# YC3122 register map
Series: ARMCM0; File version: 1.0
CPU: CM0 r1p0, little endian, no MPU, no FPU, 8 interrupt priority bits
Registers are 32-bit, read-write, reset 0x0 unless marked. A register's access mark holds for its fields unless they carry their own. Offsets are from the block's base; [hi:lo] are bit positions.

## MRCC
Base 0x000F8400
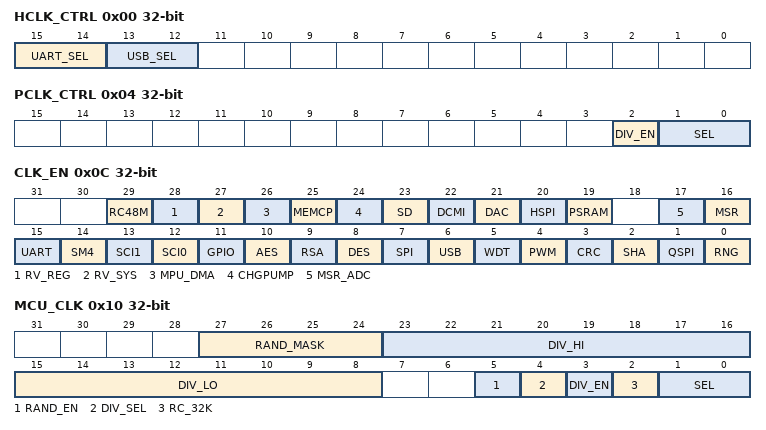
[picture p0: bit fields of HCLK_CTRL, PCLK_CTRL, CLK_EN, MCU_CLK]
0x00 HCLK_CTRL
  [15:14] UART_SEL — UART时钟clk_uart选择。 0: rc192m分频后生成的48M时钟 1: pll_hsi_48m,切换PLL频率会抖动 2: pll_hse_48m,切换PLL频率会抖动
  [13:12] USB_SEL — USB时钟clk_usb选择。 0: rc192m分频后生成的48M时钟 1: pll_hsi_48m,切换PLL频率会抖动 2: pll_hse_48m,切换PLL频率会抖动
0x04 PCLK_CTRL
  [2] DIV_EN — PCLK分频使能
  [1:0] SEL — PCLK使用的分频值选择 0: 1分频 1: 2分频 2: 4分频 3: 8分频
0x08 RSA_CLK
  [3:0] CLK_CFG — 每16个clk_rsa中,前n个可以强制为0,此 寄存器用于选择n值,从这里输出的时钟最终给到RSA模块1 : 每16个clk_rsa中,前3个周期强制为0. 2, 4, 5 :每16个clk_rsa中,前2个周期强 制为0. 3 : 每16个clk_rsa中,第一个强制为0. 6, 7 :clk_rsa输入等于输出 Others : 每16个clk_rsa中,前7个周期强 制为0
0x0C CLK_EN
  [29] RC48M — RC48M数字模块时钟开关
  [28] RV_REG — RV_REG数字模块时钟开关
  [27] RV_SYS — RV_SYS数字模块时钟开关
  [26] MPU_DMA — MPU_DMA数字模块时钟开关
  [25] MEMCP — MEMCP数字模块时钟开关
  [24] CHGPUMP — CHGPUMP数字模块时钟开关
  [23] SD — SD数字模块时钟开关
  [22] DCMI — DCMI数字模块时钟开关
  [21] DAC — DAC数字模块时钟开关
  [20] HSPI — HSPI数字模块时钟开关
  [19] PSRAM — PSRAM数字模块时钟开关
  [17] MSR_ADC — 7811_ADC数字模块时钟开关
  [16] MSR — 7811数字模块时钟开关
  [15] UART — UART数字模块时钟开关
  [14] SM4 — SM4数字模块时钟开关
  [13] SCI1 — SCI1数字模块时钟开关
  [12] SCI0 — SCI0数字模块时钟开关
  [11] GPIO — GPIO数字模块时钟开关
  [10] AES — AES数字模块时钟开关
  [9] RSA — RSA数字模块时钟开关
  [8] DES — DES数字模块时钟开关
  [7] SPI — SPI数字模块时钟开关
  [6] USB — USB数字模块时钟开关
  [5] WDT — WDT数字模块时钟开关
  [4] PWM — PWM数字模块时钟开关
  [3] CRC — CRC数字模块时钟开关
  [2] SHA — SHA数字模块时钟开关
  [1] QSPI — qspi数字模块时钟开关
  [0] RNG — rng数字模块时钟开关
0x10 MCU_CLK
  [27:24] RAND_MASK — DIV_HI和DIV_LO会加上(随机数& RA. ND_MASK)
  [23:16] DIV_HI — 输入给MCU的时钟的低电平持续时间 = (DIV _HI +1)个clk
  [15:8] DIV_LO — 输入给MCU的时钟的低电平持续时间 = (DIV _LO+1)个clk
  [5] RAND_EN — 为1则使能MCU时钟随机功能
  [4] DIV_SEL — MCU时钟分频选择 0：选择非分频时钟作为 clk_mcu. 1：选择分频时钟作为clk_mcu 注意：当从'1'变为'0'时,应先设置div_sel为' 0',延迟至少两个周期,然后清除div_en,不要同时清 除这两位。当从'0'变为'1'时,应先设置div_en为 '1',延迟至少两个周期,然后设置
  [3] DIV_EN — 为1则使能MCU时钟分频
  [2] RC_32K — 为1则使能内部RC32K（LSI）为系统时钟,同 时屏蔽其他所有的设置
  [1:0] SEL — MCU时钟来源选择 0: rc192m. 1: pll_192M. 2: pll_256M. 3: pll_48M,
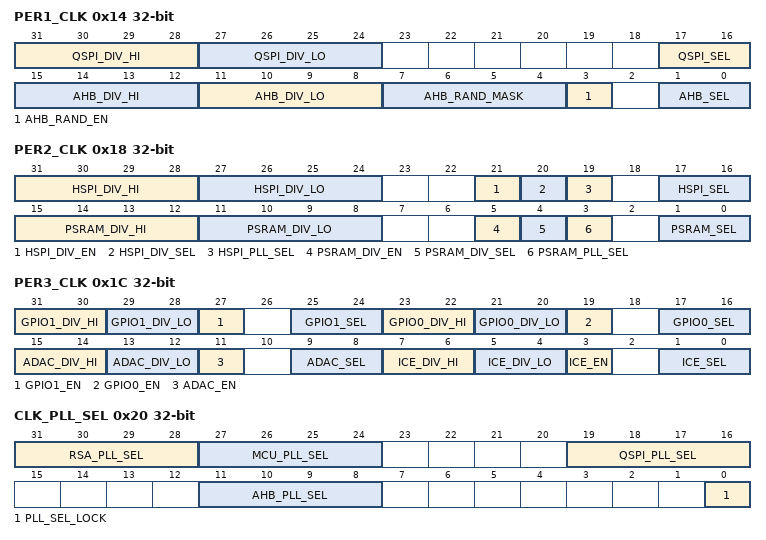
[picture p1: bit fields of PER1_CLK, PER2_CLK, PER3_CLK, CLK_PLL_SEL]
0x14 PER1_CLK
  [31:28] QSPI_DIV_HI — 输入给QSPI的时钟的低电平持续时间 = (QS. PI_DIV_HI+1)个clk
  [27:24] QSPI_DIV_LO — 输入给QSPI的时钟的低电平持续时间 = (QS. PI_DIV_LO+1)个clk
  [17:16] QSPI_SEL — QSPI总线时钟来源选择 0: CLK_MCU. 1: RC192M. 2: pll_192M. 3: pll_48M
  [15:12] AHB_DIV_HI — 输入给AHB的时钟的高电平持续时间 = (AHB _DIV_HI +1)个clk
  [11:8] AHB_DIV_LO — 输入给AHB的时钟的低电平持续时间 = (AHB _DIV_LO+1)个clk
  [7:4] AHB_RAND_MASK — AHB_DIV_HI和AHB_DIV_LO会加上 (随机数&AHB_RAND_MASK)
  [3] AHB_RAND_EN — 为1则使能AHB总线时钟随机功能
  [1:0] AHB_SEL — AHB总线时钟来源选择 0: CLK_MCU. 1: RC192M. 2: pll_192M. 3: pll_48M
0x18 PER2_CLK
  [31:28] HSPI_DIV_HI — 输入给HSPI的时钟的高电平持续时间 = (HS. PI_DIV_HI +1)个clk
  [27:24] HSPI_DIV_LO — 输入给HSPI的时钟的低电平持续时间 = (HS. PI_DIV_LO+1)个clk
  [21] HSPI_DIV_EN — 为1则使能HSPI时钟分频
  [20] HSPI_DIV_SEL — HSPI时钟分频选择 0：选择非分频时钟作为 clk_hspi. 1：选择分频时钟作为 clk_hspi
  [19] HSPI_PLL_SEL — HSPI时钟来源选择 0: pll_hsi. 1: pll_hse
  [17:16] HSPI_SEL — PSRAM总线时钟来源选择 0: CLK_MCU. 1: RC192M. 2: pll_192M. 3: pll_256M
  [15:12] PSRAM_DIV_HI — 输入给PSRAM的时钟的高电平持续时间 = (P. SRAM_DIV_HI +1)个clk
  [11:8] PSRAM_DIV_LO — 输入给PSRAM的时钟的低电平持续时间 = (P. SRAM_DIV_LO+1)个clk
  [5] PSRAM_DIV_EN — 为1则使能PSRAM时钟分频
  [4] PSRAM_DIV_SEL — PSRAM时钟分频选择 0：选择非分频时钟作为 clk_psram. 1：选择分频时钟作为clk_psram
  [3] PSRAM_PLL_SEL — PSRAM时钟来源选择 0: pll_hsi. 1: pll_hse
  [1:0] PSRAM_SEL — PSRAM总线时钟来源选择 0: CLK_MCU. 1: RC192M. 2: pll_192M. 3: pll_256M
0x1C PER3_CLK
  [31:30] GPIO1_DIV_HI — GPIO奇数脚输出的时钟的高电平持续时间 = ( GPIO1_DIV_HI+1)个clk
  [29:28] GPIO1_DIV_LO — GPIO奇数脚输出的时钟的低电平持续时间 = ( GPIO1_DIV_LO+1)个clk
  [27] GPIO1_EN — GPIO奇数脚时钟输出使能
  [25:24] GPIO1_SEL — GPIO奇数脚时钟输出,需要把奇数的GPIO配置 成 55:GPIO_CLK_OUT. 0: clk_rc48m. 1: clk_pll_hsi_48m. 2: clk_pll_hse_48m
  [23:22] GPIO0_DIV_HI — GPIO偶数脚输出的时钟的高电平持续时间 = ( GPIO0_DIV_HI+1)个clk
  [21:20] GPIO0_DIV_LO — GPIO偶数脚输出的时钟的低电平持续时间 = ( GPIO0_DIV_LO+1)个clk
  [19] GPIO0_EN — GPIO偶数脚时钟输出使能
  [17:16] GPIO0_SEL — GPIO偶数脚时钟输出,需要把偶数的GPIO配置 成 55:GPIO_CLK_OUT. 0: clk_rc48m. 1: clk_pll_hsi_48m. 2: clk_pll_hse_48m
  [15:14] ADAC_DIV_HI — 输入给ADAC的时钟的高电平持续时间 = (AD. AC_DIV_HI +1)个clk
  [13:12] ADAC_DIV_LO — 输入给ADAC的时钟的低电平持续时间 = (AD. AC_DIV_LO+1)个clk
  [11] ADAC_EN — ADAC时钟分频使能来源选择 0：选择非分频时钟作为 clk_adac. 1：选择分频时钟作为clk_adac
  [9:8] ADAC_SEL — ADAC时钟来源选择 0: rc48m. 1: pll_hsi_48m. 2: pll_hse_48m
  [7:6] ICE_DIV_HI — 输入给ICE的时钟的高电平持续时间 = (ICE _DIV_HI +1)个clk
  [5:4] ICE_DIV_LO — 输入给ICE的时钟的低电平持续时间 = (ICE _DIV_LO+1)个clk
  [3] ICE_EN — ICE时钟分频使能来源选择 0：选择非分频时钟作为 clk_ice. 1：选择分频时钟作为clk_ice
  [1:0] ICE_SEL — ICE时钟来源选择 0: rc48m. 1: pll_hsi_48m. 2: pll_hse_48m
0x20 CLK_PLL_SEL
  [31:28] RSA_PLL_SEL — RSA的时钟来源选择 0x5: PLL_HSE. Others:PLL_HSI
  [27:24] MCU_PLL_SEL — MCU的时钟来源选择 0x5: PLL_HSE. Others:PLL_HSI
  [19:16] QSPI_PLL_SEL — QSPI的时钟来源选择 0x5: PLL_HSE. Others:PLL_HSI
  [11:8] AHB_PLL_SEL — AHB的时钟来源选择 0x5: PLL_HSE. Others:PLL_HSI
  [0] PLL_SEL_LOCK — 为1后锁定AHB,QSPI,MCU,RSA的时钟 选择,且无法解锁。
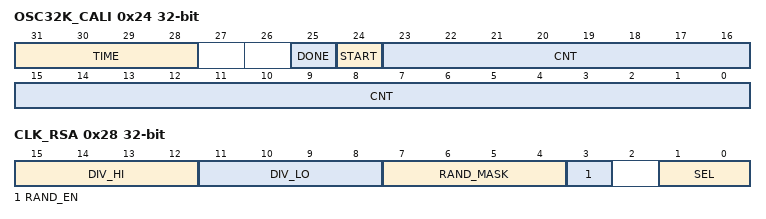
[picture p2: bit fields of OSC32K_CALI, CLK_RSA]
0x24 OSC32K_CALI
  [31:28] TIME — 校准持续时长,校准时间长度为(2^cali_ti me)个 OSC32K 周期
  [25] DONE ro — 校准完成信号 校准开始后,此信号会变成'0',校准完成后,此信号会变为 '1'
  [24] START — 校准启动信号 写'1'后,延迟1us,再写'0',上升沿触发校准开始
  [23:0] CNT ro — time所表示的时间长度内,48M时钟计数值 注意：校准时钟源使用的是clk_gpio1_sel选择的 48M时钟
0x28 CLK_RSA
  [15:12] DIV_HI — 输入给RSA的时钟的高电平持续时间 = (DIV _HI+1)个clk
  [11:8] DIV_LO — 输入给RSA的时钟的低电平持续时间 = (DIV _LO+1)个clk
  [7:4] RAND_MASK — DIV_HI和DIV_LO会加上(随机数& RA. ND_MASK)
  [3] RAND_EN — RSA时钟随机使能 0:失能RSA时钟随机 1:使能RSA时钟随机
  [1:0] SEL — RSA时钟来源选择 0: cpu. 1: rc192m. 2: pll_out_norm, (192M). 3: pll_out_max, (256M)
